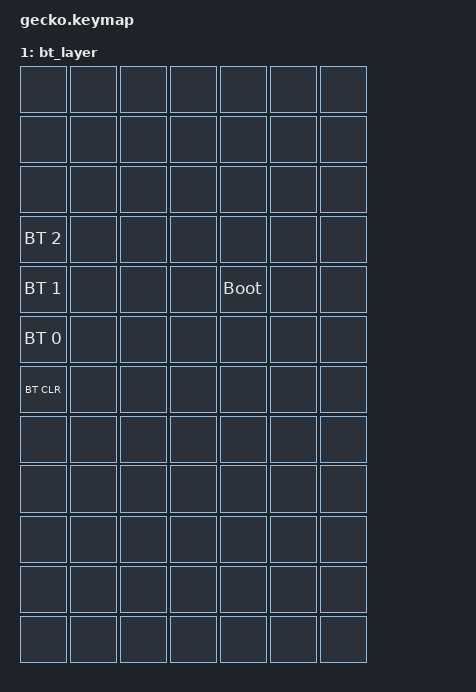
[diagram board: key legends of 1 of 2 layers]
#include <behaviors.dtsi>
#include <dt-bindings/zmk/keys.h>
#include <dt-bindings/zmk/bt.h>

/ {
    keymap {
        compatible = "zmk,keymap";
        default_layer {
            bindings = <
                &kp RBKT &kp FSLH &kp SEMICOLON &kp P &kp N0 &none &none  // row 0
                &kp N5 &kp T &kp G &kp B &kp RIGHT &none &none   // row 1
                &kp N4 &kp R &kp F &kp V &none &none &kp END   // row 2
                &kp N3 &kp E &kp D &kp C &kp LEFT &kp BSPC &kp HOME // row 3
                &kp N2 &kp W &kp S &kp X &mo 1 &kp DEL &none   // row 4
                &kp N1 &kp Q &kp A &kp Z &kp GRAVE &kp LCTRL &kp LALT   // row 5
                &kp EQUAL &kp TAB &kp CAPS &kp LSHFT &none &none &none   // row 6
                &kp UP &kp N &kp H &kp Y &kp N6 &kp SPACE &kp PG_DN // row 7
                &none &kp M &kp J &kp U &kp N7 &kp ENTER &none // row 8
                &kp DOWN &kp COMMA &kp K &kp I &kp N8 &kp RCTRL &kp PG_UP  // row 9
                &kp LBKT &kp DOT &kp L &kp O &kp N9 &kp N7 &kp RCMD // row 10
                &none &kp RSHFT &kp APOS &kp BSLH &kp MINUS &none // row 11
            >;
        };
        bt_layer {
            bindings = <
                &none &none &none &none &none &none &none  // row 0
                &none &none &none &none &none &none &none  // row 1
                &none &none &none &none &none &none &none  // row 2
                &bt BT_SEL 2 &none &none &none &none &none &none  // row 3
                &bt BT_SEL 1 &none &none &none &bootloader &none &none  // row 4
                &bt BT_SEL 0 &none &none &none &none &none &none  // row 5
                &bt BT_CLR &none &none &none &none &none &none  // row 6
                &none &none &none &none &none &none &none  // row 7
                &none &none &none &none &none &none &none  // row 8
                &none &none &none &none &none &none &none  // row 9
                &none &none &none &none &none &none &none  // row 10
                &none &none &none &none &none &none &none  // row 11
            >;
        };
    };
};
